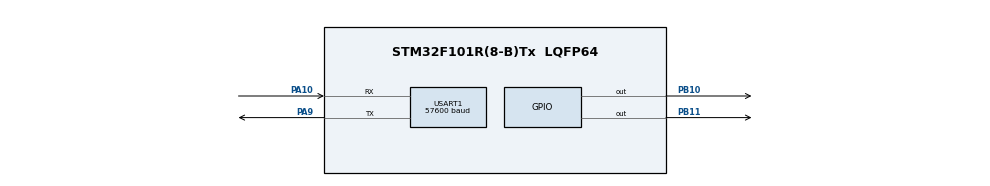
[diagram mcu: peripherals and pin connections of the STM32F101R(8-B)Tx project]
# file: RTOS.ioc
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Mcu.Family=STM32F1
FREERTOS.Tasks01=defaultTask,24,128,StartDefaultTask,Default,NULL,Dynamic,NULL,NULL
PA10.Mode=Asynchronous
USART1.BaudRate=57600
PD0-OSC_IN.Signal=RCC_OSC_IN
PB11.Signal=GPIO_Output
VP_SYS_VS_ND.Mode=No_Debug
ProjectManager.StackSize=0x400
VP_FREERTOS_VS_CMSIS_V2.Mode=CMSIS_V2
PD1-OSC_OUT.Signal=RCC_OSC_OUT
PA13.Signal=SYS_JTMS-SWDIO
PA9.Mode=Asynchronous
ProjectManager.TargetToolchain=STM32CubeIDE
PA9.Signal=USART1_TX
PB10.Signal=GPIO_Output
board=custom
RCC.APB2Freq_Value=8000000
NVIC.TIM2_IRQn=true\:0\:0\:false\:false\:true\:false\:false\:true
Mcu.Name=STM32F101R(8-B)Tx
Mcu.Package=LQFP64
VP_SYS_VS_tim2.Mode=TIM2
NVIC.TimeBase=TIM2_IRQn
USART1.VirtualMode=VM_ASYNC
NVIC.TimeBaseIP=TIM2
PA10.Signal=USART1_RX
PA14.Signal=SYS_JTCK-SWCLK
ProjectManager.HeapSize=0x200
NVIC.PriorityGroup=NVIC_PRIORITYGROUP_4
RCC.APB1Freq_Value=8000000

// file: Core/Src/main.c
/* USER CODE BEGIN Header */
/**
  ******************************************************************************
  * @file           : main.c
  * @brief          : Main program body
  ******************************************************************************
  * @attention
  *
  * <h2><center>&copy; Copyright (c) 2021 STMicroelectronics.
  * All rights reserved.</center></h2>
  *
  * This software component is licensed by ST under BSD 3-Clause license,
  * the "License"; You may not use this file except in compliance with the
  * License. You may obtain a copy of the License at:
  *                        opensource.org/licenses/BSD-3-Clause
  *
  ******************************************************************************
  */
/* USER CODE END Header */
#include "main.h"
#include "cmsis_os.h"

UART_HandleTypeDef huart1;

/* Definitions for defaultTask */
osThreadId_t defaultTaskHandle;
const osThreadAttr_t defaultTask_attributes = {
  .name = "defaultTask",
  .stack_size = 128 * 4,
  .priority = (osPriority_t) osPriorityNormal,
};

void SystemClock_Config(void);
static void MX_GPIO_Init(void);
static void MX_USART1_UART_Init(void);
void StartDefaultTask(void *argument);

int main(void)
{

  /* MCU Configuration--------------------------------------------------------*/

  /* Reset of all peripherals, Initializes the Flash interface and the Systick. */
  HAL_Init();

  /* Configure the system clock */
  SystemClock_Config();

  /* Initialize all configured peripherals */
  MX_GPIO_Init();
  MX_USART1_UART_Init();
  /* USER CODE BEGIN 2 */
  HAL_GPIO_WritePin(GPIOB, GPIO_PIN_10, GPIO_PIN_SET);
  HAL_GPIO_WritePin(GPIOB, GPIO_PIN_11, GPIO_PIN_SET);
  /* USER CODE END 2 */

  /* Init scheduler */
  osKernelInitialize();

  /* Create the thread(s) */
  /* creation of defaultTask */
  defaultTaskHandle = osThreadNew(StartDefaultTask, NULL, &defaultTask_attributes);

  /* Start scheduler */
  osKernelStart();

  /* We should never get here as control is now taken by the scheduler */
  /* Infinite loop */
  while (1)
  {

  }
}

void SystemClock_Config(void)
{
  RCC_OscInitTypeDef RCC_OscInitStruct = {0};
  RCC_ClkInitTypeDef RCC_ClkInitStruct = {0};

  /** Initializes the RCC Oscillators according to the specified parameters
  * in the RCC_OscInitTypeDef structure.
  */
  RCC_OscInitStruct.OscillatorType = RCC_OSCILLATORTYPE_HSI;
  RCC_OscInitStruct.HSIState = RCC_HSI_ON;
  RCC_OscInitStruct.HSICalibrationValue = RCC_HSICALIBRATION_DEFAULT;
  RCC_OscInitStruct.PLL.PLLState = RCC_PLL_NONE;
  if (HAL_RCC_OscConfig(&RCC_OscInitStruct) != HAL_OK)
  {
    Error_Handler();
  }
  /** Initializes the CPU, AHB and APB buses clocks
  */
  RCC_ClkInitStruct.ClockType = RCC_CLOCKTYPE_HCLK|RCC_CLOCKTYPE_SYSCLK
                              |RCC_CLOCKTYPE_PCLK1|RCC_CLOCKTYPE_PCLK2;
  RCC_ClkInitStruct.SYSCLKSource = RCC_SYSCLKSOURCE_HSI;
  RCC_ClkInitStruct.AHBCLKDivider = RCC_SYSCLK_DIV1;
  RCC_ClkInitStruct.APB1CLKDivider = RCC_HCLK_DIV1;
  RCC_ClkInitStruct.APB2CLKDivider = RCC_HCLK_DIV1;

  if (HAL_RCC_ClockConfig(&RCC_ClkInitStruct, FLASH_LATENCY_0) != HAL_OK)
  {
    Error_Handler();
  }
}

static void MX_USART1_UART_Init(void)
{

  huart1.Instance = USART1;
  huart1.Init.BaudRate = 115200;
  huart1.Init.WordLength = UART_WORDLENGTH_8B;
  huart1.Init.StopBits = UART_STOPBITS_1;
  huart1.Init.Parity = UART_PARITY_NONE;
  huart1.Init.Mode = UART_MODE_TX_RX;
  huart1.Init.HwFlowCtl = UART_HWCONTROL_NONE;
  huart1.Init.OverSampling = UART_OVERSAMPLING_16;
  if (HAL_UART_Init(&huart1) != HAL_OK)
  {
    Error_Handler();
  }

}

static void MX_GPIO_Init(void)
{
  GPIO_InitTypeDef GPIO_InitStruct = {0};

  /* GPIO Ports Clock Enable */
  __HAL_RCC_GPIOD_CLK_ENABLE();
  __HAL_RCC_GPIOB_CLK_ENABLE();
  __HAL_RCC_GPIOA_CLK_ENABLE();

  /*Configure GPIO pin Output Level */
  HAL_GPIO_WritePin(GPIOB, GPIO_PIN_10|GPIO_PIN_11, GPIO_PIN_RESET);

  /*Configure GPIO pins : PB10 PB11 */
  GPIO_InitStruct.Pin = GPIO_PIN_10|GPIO_PIN_11;
  GPIO_InitStruct.Mode = GPIO_MODE_OUTPUT_PP;
  GPIO_InitStruct.Pull = GPIO_NOPULL;
  GPIO_InitStruct.Speed = GPIO_SPEED_FREQ_LOW;
  HAL_GPIO_Init(GPIOB, &GPIO_InitStruct);

}

void StartDefaultTask(void *argument)
{
  for(;;)
  {
    osDelay(1);
  }
}

 /**
  * @brief  Period elapsed callback in non blocking mode
  * @note   This function is called  when TIM2 interrupt took place, inside
  * HAL_TIM_IRQHandler(). It makes a direct call to HAL_IncTick() to increment
  * a global variable "uwTick" used as application time base.
  * @param  htim : TIM handle
  * @retval None
  */
void HAL_TIM_PeriodElapsedCallback(TIM_HandleTypeDef *htim)
{
  if (htim->Instance == TIM2) {
    HAL_IncTick();
  }
}

void Error_Handler(void)
{
  __disable_irq();
  while (1)
  {
  }
}

/************************ (C) COPYRIGHT STMicroelectronics *****END OF FILE****/
